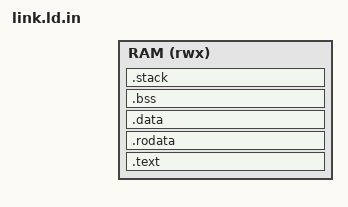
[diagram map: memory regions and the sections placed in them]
/*
 * KISS Open License Version 1.0 (KOL-v1)
 *
 * SPDX-FileCopyrightText: 2026 I-plusplus Inc.
 * SPDX-License-Identifier: LicenseRef-KOL-v1
 *
 * Copyright remains with its respective holders; original copyright and attribution notices must be preserved.
 * Contributors may add copyright notices for their own original modifications.
 * Distributed modifications must be identified as required by Section 4(c) of KOL-v1.
 *
 * Use, modification, distribution, and incorporation into commercial or proprietary software are permitted
 * without license fees or source disclosure, subject to all terms of the complete KOL-v1 license.
 *
 * Contributors grant the patent permissions stated in KOL-v1. Outputs are not covered merely because a
 * KOL-licensed tool produced them; embedded licensed material remains subject to applicable license terms.
 *
 * THIS SOFTWARE IS PROVIDED "AS IS", WITHOUT WARRANTY OR LIABILITY TO THE EXTENT PERMITTED BY APPLICABLE LAW.
 *
 * This header is a summary, not a separate license or an amendment to KOL-v1.
 * All terms and conditions of KOL-v1 apply. See the accompanying LICENSE file for the complete license text.
 */

/* Environment validation only. RAM is checked against the emitted DTB. */
ENTRY(_start)
MEMORY { RAM (rwx) : ORIGIN = @ORIGIN@, LENGTH = @LENGTH@ }
SECTIONS {
  .text : { KEEP(*(.text.boot)) *(.text .text.*) } > RAM
  .rodata : { *(.rodata .rodata.*) } > RAM
  .data : { *(.data .data.*) } > RAM
  .bss (NOLOAD) : {
    . = ALIGN(16); __bss_start = .;
    *(.bss .bss.*) *(COMMON)
    . = ALIGN(16); __bss_end = .;
  } > RAM
  .stack (NOLOAD) : {
    . = ALIGN(16); . += 0x10000; __stack_top = .;
  } > RAM
  /DISCARD/ : { *(.comment) *(.note*) *(.eh_frame*) }
}
ASSERT((__stack_top & 15) == 0, "SP must be 16-byte aligned")
